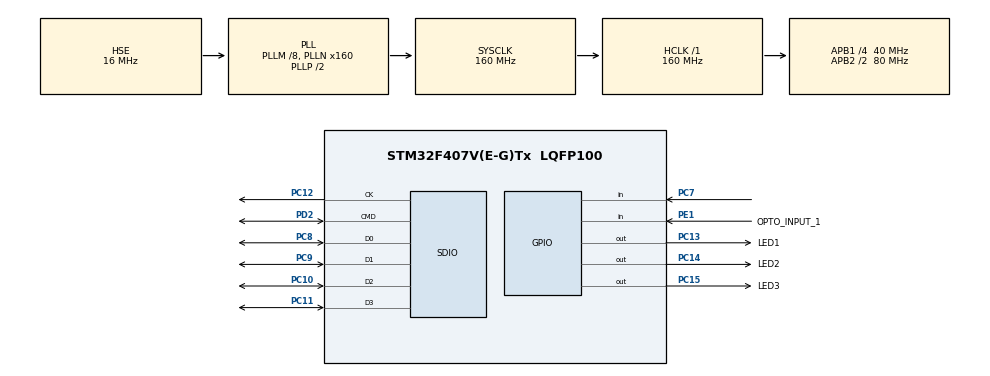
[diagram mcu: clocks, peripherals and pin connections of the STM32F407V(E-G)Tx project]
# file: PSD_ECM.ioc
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Dma.Request0=SDIO_TX
Dma.Request1=SDIO_RX
Dma.SDIO_RX.1.Direction=DMA_PERIPH_TO_MEMORY
Dma.SDIO_RX.1.FIFOMode=DMA_FIFOMODE_ENABLE
Dma.SDIO_RX.1.FIFOThreshold=DMA_FIFO_THRESHOLD_FULL
Dma.SDIO_RX.1.Instance=DMA2_Stream6
Dma.SDIO_RX.1.MemBurst=DMA_MBURST_INC4
Dma.SDIO_RX.1.MemDataAlignment=DMA_MDATAALIGN_WORD
Dma.SDIO_RX.1.MemInc=DMA_MINC_ENABLE
Dma.SDIO_RX.1.Mode=DMA_PFCTRL
Dma.SDIO_RX.1.PeriphBurst=DMA_PBURST_INC4
Dma.SDIO_RX.1.PeriphDataAlignment=DMA_PDATAALIGN_WORD
Dma.SDIO_RX.1.PeriphInc=DMA_PINC_DISABLE
Dma.SDIO_RX.1.Priority=DMA_PRIORITY_LOW
Dma.SDIO_TX.0.Direction=DMA_MEMORY_TO_PERIPH
Dma.SDIO_TX.0.FIFOMode=DMA_FIFOMODE_ENABLE
Dma.SDIO_TX.0.FIFOThreshold=DMA_FIFO_THRESHOLD_FULL
Dma.SDIO_TX.0.Instance=DMA2_Stream3
Dma.SDIO_TX.0.MemBurst=DMA_MBURST_INC4
Dma.SDIO_TX.0.MemDataAlignment=DMA_MDATAALIGN_WORD
Dma.SDIO_TX.0.MemInc=DMA_MINC_ENABLE
Dma.SDIO_TX.0.Mode=DMA_PFCTRL
Dma.SDIO_TX.0.PeriphBurst=DMA_PBURST_INC4
Dma.SDIO_TX.0.PeriphDataAlignment=DMA_PDATAALIGN_WORD
Dma.SDIO_TX.0.PeriphInc=DMA_PINC_DISABLE
Dma.SDIO_TX.0.Priority=DMA_PRIORITY_LOW
FATFS.BSP.number=1
FATFS.USE_DMA_CODE_SD=1
FATFS._MAX_SS=4096
FATFS0.BSP.STBoard=false
FATFS0.BSP.api=Unknown
FATFS0.BSP.i2caddr=0
FATFS0.BSP.instance=PC7
FATFS0.BSP.ip=GPIO
FATFS0.BSP.mode=Input
FATFS0.BSP.name=Detect_SDIO
FATFS0.BSP.solution=PC7
Mcu.Family=STM32F4
Mcu.Name=STM32F407V(E-G)Tx
Mcu.Package=LQFP100
NVIC.DMA2_Stream3_IRQn=true\:0\:0\:false\:false\:true\:false\:true
NVIC.DMA2_Stream6_IRQn=true\:0\:0\:false\:false\:true\:false\:true
NVIC.PriorityGroup=NVIC_PRIORITYGROUP_4
NVIC.SDIO_IRQn=true\:0\:0\:false\:false\:true\:true\:true
NVIC.TIM1_UP_TIM10_IRQn=true\:0\:0\:false\:false\:true\:true\:true
PA13.Mode=Serial_Wire
PA13.Signal=SYS_JTMS-SWDIO
PA14.Mode=Serial_Wire
PA14.Signal=SYS_JTCK-SWCLK
PC10.GPIO_PuPd=GPIO_PULLUP
PC10.Mode=SD_4_bits_Wide_bus
PC10.Signal=SDIO_D2
PC11.GPIO_PuPd=GPIO_PULLUP
PC11.Mode=SD_4_bits_Wide_bus
PC11.Signal=SDIO_D3
PC12.GPIO_PuPd=GPIO_NOPULL
PC12.Mode=SD_4_bits_Wide_bus
PC12.Signal=SDIO_CK
PC13-ANTI_TAMP.GPIO_Label=LED1
PC13-ANTI_TAMP.Signal=GPIO_Output
PC14-OSC32_IN.GPIO_Label=LED2
PC14-OSC32_IN.Signal=GPIO_Output
PC15-OSC32_OUT.GPIO_Label=LED3
PC15-OSC32_OUT.Signal=GPIO_Output
PC7.GPIO_PuPd=GPIO_PULLUP
PC7.Signal=GPIO_Input
PC8.GPIO_PuPd=GPIO_PULLUP
PC8.Mode=SD_4_bits_Wide_bus
PC8.Signal=SDIO_D0
PC9.GPIO_PuPd=GPIO_PULLUP
PC9.Mode=SD_4_bits_Wide_bus
PC9.Signal=SDIO_D1
PD2.GPIO_PuPd=GPIO_PULLUP
PD2.Mode=SD_4_bits_Wide_bus
PD2.Signal=SDIO_CMD
PE1.GPIO_Label=OPTO_INPUT_1
PE1.Signal=GPIO_Input
PH0-OSC_IN.Mode=HSE-External-Oscillator
PH0-OSC_IN.Signal=RCC_OSC_IN
PH1-OSC_OUT.Mode=HSE-External-Oscillator
PH1-OSC_OUT.Signal=RCC_OSC_OUT
ProjectManager.HeapSize=0x2000
ProjectManager.StackSize=0x4000
ProjectManager.TargetToolchain=STM32CubeIDE
RCC.48MHZClocksFreq_Value=45714285.71428572
RCC.AHBFreq_Value=160000000
RCC.APB1CLKDivider=RCC_HCLK_DIV4
RCC.APB1Freq_Value=40000000
RCC.APB1TimFreq_Value=80000000
RCC.APB2CLKDivider=RCC_HCLK_DIV2
RCC.APB2Freq_Value=80000000
RCC.APB2TimFreq_Value=160000000
RCC.CortexFreq_Value=160000000
RCC.HCLKFreq_Value=160000000
RCC.HSE_VALUE=16000000
RCC.HSI_VALUE=16000000
RCC.LSE_VALUE=32768
RCC.PLLM=8
RCC.PLLN=160
RCC.PLLQ=7
RCC.PLLSourceVirtual=RCC_PLLSOURCE_HSE
RCC.SYSCLKFreq_VALUE=160000000
RCC.SYSCLKSource=RCC_SYSCLKSOURCE_PLLCLK
RCC.VCOOutputFreq_Value=320000000
SDIO.ClockDiv=10
TIM10.Period=7999
TIM10.Prescaler=9999
VP_FATFS_VS_SDIO.Mode=SDIO
VP_TIM10_VS_ClockSourceINT.Mode=Enable_Timer
board=custom

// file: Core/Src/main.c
/* USER CODE BEGIN Header */
/**
 ******************************************************************************
 * @file           : main.c
 * @brief          : ECM Module software
 * @author			: Szymon Kacperek
 * @date			: 14/08/2020
 ******************************************************************************
 * Code created by me is signed in longer * arrays. Naming is adapted to Google C/C++ Style Guide.
 *
 * NOTES
 * @ 9/09 CAN is set on different pins than on .sch. Set for test purposes.
 *
 ******************************************************************************
 */
/* USER CODE END Header */
#include "main.h"
#include "dma.h"
#include "fatfs.h"
#include "sdio.h"
#include "tim.h"
#include "gpio.h"

/* USER CODE BEGIN Includes */

/************************************************************************************************
 PRIVATE INCLUDES
 ************************************************************************************************/
#include "canopen_object_dict.h"
#include "stdbool.h"

/* USER CODE END Includes */

/* USER CODE BEGIN PV */
/************************************************************************************************
 PRIVATE VARIABLES
 ************************************************************************************************/
//FATFS myFatFS;
//FIL myFile;
//FRESULT fresult;
/* USER CODE END PV */

void SystemClock_Config(void);

int main(void)
{

  /* MCU Configuration--------------------------------------------------------*/

  /* Reset of all peripherals, Initializes the Flash interface and the Systick. */
  HAL_Init();

  /* Configure the system clock */
  SystemClock_Config();

  /* Initialize all configured peripherals */
  MX_GPIO_Init();
  MX_DMA_Init();
  MX_TIM10_Init();
  MX_SDIO_SD_Init();
  MX_FATFS_Init();
  /* USER CODE BEGIN 2 */

	/************************************************************************************************
	 CAN PERIPHERIAL AND ITS COMPONENTS
	 ************************************************************************************************/
//	CanopenObjectDictInit();
//	CanConfigFilter(CAN_HIGH_SPEED, 0, 0x0000, 0x0000, 0x0000, 0x0000);
//	CanInit(CAN_HIGH_SPEED);
//	CanInit(CAN_LOW_SPEED);
//	HAL_TIM_Base_Start_IT(&htim10);
	/************************************************************************************************
	 TURNING ON THE MODULES
	 ************************************************************************************************/
//	CanSendNmt(CAN_HIGH_SPEED, OPERATIONAL_STATE, bms.node_id);
//	CanSendNmt(CAN_HIGH_SPEED, OPERATIONAL_STATE, inverter_1.node_id);
//	CanSendNmt(CAN_HIGH_SPEED, OPERATIONAL_STATE, inverter_2.node_id);
//	CanSendNmt(CAN_HIGH_SPEED, OPERATIONAL_STATE, mppt_1.node_id);
//	CanSendNmt(CAN_HIGH_SPEED, OPERATIONAL_STATE, mppt_2.node_id);
//	CanSendNmt(CAN_HIGH_SPEED, OPERATIONAL_STATE, mppt_3.node_id);
//	CanSendNmt(CAN_HIGH_SPEED, OPERATIONAL_STATE, lights_controller.node_id);
//	CanSendNmt(CAN_HIGH_SPEED, OPERATIONAL_STATE, dashboard.node_id);
	/************************************************************************************************
	 FATFS
	 ************************************************************************************************/
//	fresult = BSP_SD_Init();
//		if ((fresult) != FR_OK) {
//			HAL_GPIO_WritePin(led_red_GPIO_Port, led_red_Pin, GPIO_PIN_SET);
//		} else {
//
//	fresult = f_mount(&myFatFS, (TCHAR const*) SDPath, 0);
//	if (fresult == FR_OK) {
////	if (f_mount(&myFatFS, (TCHAR const*) SDPath, 1) == FR_OK) {
//		HAL_GPIO_WritePin(led_green_GPIO_Port, led_green_Pin, GPIO_PIN_SET);
//
//		fresult = f_open(&myFile, "TEST.TXT", FA_CREATE_ALWAYS | FA_WRITE);
//		if (fresult == FR_OK) {
////		if (f_open(&myFile, "TEST.TXT", FA_CREATE_ALWAYS | FA_WRITE) == FR_OK) {
//			HAL_GPIO_WritePin(led_orange_GPIO_Port, led_orange_Pin,
//					GPIO_PIN_SET);
//		}
//
//	} else {
//		HAL_GPIO_WritePin(led_red_GPIO_Port, led_red_Pin, GPIO_PIN_SET);
//	}
//		}
//	FRESULT res;
//	FATFS SDFatFs; /* File system object for SD disk logical drive */
//	FIL MyFile; /* File object */
//	res = f_mount(&SDFatFs, (TCHAR const*) SDPath, 1);
//	if (res != FR_OK)
//		Error_Handler();
//
//	res = f_open(&MyFile, "STM32.TXT", FA_CREATE_ALWAYS | FA_WRITE);
//	if (res != FR_OK)
//		Error_Handler();
//
//	res = f_mkdir("dir");
//	if ((res != FR_OK) && (res != FR_EXIST))
//		Error_Handler();
//
//
//
//	UINT written;
//	res = f_write(&MyFile, "hello card", 10, &written);
//	if (res != FR_OK)
//		Error_Handler();
//
//	f_close(&MyFile);
//	if (res != FR_OK)
//		Error_Handler();
//
//	FILINFO info;
//	res = f_stat("0:/STM32.TXT", &info);
//	if (res != FR_OK)
//		Error_Handler();

  /* USER CODE END 2 */

  /* Infinite loop */
	while (1) {

    /* USER CODE BEGIN 3 */
		bool wynik = HAL_GPIO_ReadPin(OPTO_INPUT_1_GPIO_Port, OPTO_INPUT_1_Pin);
		HAL_GPIO_WritePin(LED2_GPIO_Port, LED2_Pin, wynik);

		HAL_GPIO_TogglePin(LED1_GPIO_Port, LED1_Pin);
	}
  /* USER CODE END 3 */
}

void SystemClock_Config(void)
{
  RCC_OscInitTypeDef RCC_OscInitStruct = {0};
  RCC_ClkInitTypeDef RCC_ClkInitStruct = {0};

  /** Configure the main internal regulator output voltage
  */
  __HAL_RCC_PWR_CLK_ENABLE();
  __HAL_PWR_VOLTAGESCALING_CONFIG(PWR_REGULATOR_VOLTAGE_SCALE1);
  /** Initializes the RCC Oscillators according to the specified parameters
  * in the RCC_OscInitTypeDef structure.
  */
  RCC_OscInitStruct.OscillatorType = RCC_OSCILLATORTYPE_HSE;
  RCC_OscInitStruct.HSEState = RCC_HSE_ON;
  RCC_OscInitStruct.PLL.PLLState = RCC_PLL_ON;
  RCC_OscInitStruct.PLL.PLLSource = RCC_PLLSOURCE_HSE;
  RCC_OscInitStruct.PLL.PLLM = 8;
  RCC_OscInitStruct.PLL.PLLN = 160;
  RCC_OscInitStruct.PLL.PLLP = RCC_PLLP_DIV2;
  RCC_OscInitStruct.PLL.PLLQ = 7;
  if (HAL_RCC_OscConfig(&RCC_OscInitStruct) != HAL_OK)
  {
    Error_Handler();
  }
  /** Initializes the CPU, AHB and APB buses clocks
  */
  RCC_ClkInitStruct.ClockType = RCC_CLOCKTYPE_HCLK|RCC_CLOCKTYPE_SYSCLK
                              |RCC_CLOCKTYPE_PCLK1|RCC_CLOCKTYPE_PCLK2;
  RCC_ClkInitStruct.SYSCLKSource = RCC_SYSCLKSOURCE_PLLCLK;
  RCC_ClkInitStruct.AHBCLKDivider = RCC_SYSCLK_DIV1;
  RCC_ClkInitStruct.APB1CLKDivider = RCC_HCLK_DIV4;
  RCC_ClkInitStruct.APB2CLKDivider = RCC_HCLK_DIV2;

  if (HAL_RCC_ClockConfig(&RCC_ClkInitStruct, FLASH_LATENCY_5) != HAL_OK)
  {
    Error_Handler();
  }
}

void Error_Handler(void)
{
  /* USER CODE BEGIN Error_Handler_Debug */
	/* User can add his own implementation to report the HAL error return state */
	while (1) {
		HAL_GPIO_TogglePin(LED1_GPIO_Port, LED1_Pin);
		HAL_Delay(500);
	}
  /* USER CODE END Error_Handler_Debug */
}

/************************ (C) COPYRIGHT STMicroelectronics *****END OF FILE****/
